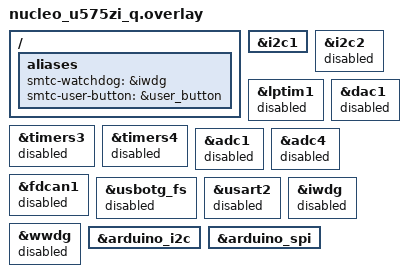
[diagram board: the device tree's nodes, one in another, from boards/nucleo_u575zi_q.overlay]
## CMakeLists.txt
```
# Copyright (c) 2024 Semtech Corporation
# SPDX-License-Identifier: Apache-2.0

cmake_minimum_required(VERSION 3.13.1)

find_package(Zephyr REQUIRED HINTS $ENV{ZEPHYR_BASE})
project(flrp_api_lorawan)

zephyr_include_directories(
  ${CMAKE_CURRENT_SOURCE_DIR}/src/
  ${CMAKE_CURRENT_SOURCE_DIR}/../../sdk/ranging_demo/src
)

target_sources(app PRIVATE
  ${CMAKE_CURRENT_SOURCE_DIR}/src/main.c
  ${CMAKE_CURRENT_SOURCE_DIR}/src/flrp_api.c
  ${CMAKE_CURRENT_SOURCE_DIR}/src/flrp_api_menu.c
  ${CMAKE_CURRENT_SOURCE_DIR}/src/flrp_remote.c
  ${CMAKE_CURRENT_SOURCE_DIR}/src/flrp_display.c
  ${CMAKE_CURRENT_SOURCE_DIR}/../../sdk/ranging_demo/src/oled_display.c
)
```

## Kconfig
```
# Copyright (c) 2026 Semtech Corporation
# SPDX-License-Identifier: Apache-2.0

menu "FLRP API lorawan sample defaults"

config FLRP_TEST_APPLY_DEFAULT_CONFIG
	bool "Apply FLRP testing defaults at boot (crypto off, fixed EUIs)"
	default n

config DISPLAY_THREAD_PRIORITY
	int "Display task priority"
	default 5
	help
	  Priority of the FLRP display task.

# Sample policy: enable sentinel only when MPU guard is off
config STACK_SENTINEL
	default y if !MPU_STACK_GUARD

config ICACHE
	default y if CPU_HAS_ICACHE

config DCACHE
	default y if CPU_HAS_DCACHE
	
config STM32_FLASH_PREFETCH
	depends on HAS_STM32_FLASH_PREFETCH
	default y

endmenu

source "Kconfig.zephyr"
```

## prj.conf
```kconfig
# Copyright (c) 2024 Semtech Corporation
# SPDX-License-Identifier: Apache-2.0

CONFIG_SPEED_OPTIMIZATIONS=y          # -O2 ou -O3
CONFIG_SIZE_OPTIMIZATIONS=n           # Vitesse > taille

# --------------------------- General configuration ---------------------------

CONFIG_USE_SEGGER_RTT=n

# heap size
CONFIG_HEAP_MEM_POOL_SIZE=4096

CONFIG_LOG=y

CONFIG_TEST_RANDOM_GENERATOR=y

CONFIG_PM_DEVICE=y

CONFIG_WATCHDOG=n

CONFIG_FLASH=y

CONFIG_I2C=y

CONFIG_EVENTS=y

# ------------------------------ Transceiver driver ----------------------------

CONFIG_LORA_BASICS_MODEM_DRIVERS=y
CONFIG_LORA_BASICS_MODEM_DRIVERS_EVENT_TRIGGER_GLOBAL_THREAD=n
CONFIG_LORA_BASICS_MODEM_DRIVERS_EVENT_TRIGGER_NO_THREAD=y

# ------------------------------ LoRa Basics Modem -----------------------------

CONFIG_USP_LORA_BASICS_MODEM=y

CONFIG_LORA_BASICS_MODEM_RELAY_TX=n

# ------------------------------ USP -----------------------------

CONFIG_USP=y
CONFIG_USP_FLRP=y
CONFIG_USP_MAIN_THREAD=y

#CONFIG_USP_LOG_LEVEL_DBG=y

CONFIG_MAIN_STACK_SIZE=4096

# Debug stack (à enlever en production)
CONFIG_THREAD_STACK_INFO=y
CONFIG_THREAD_MONITOR=y
CONFIG_THREAD_NAME=y

# Threads are cooperative (non-preemptive) to simplify critical section management and avoid complex synchronization.
# This approach may reduce reactivity when ISR (interrupt service routines) are triggered (low optimization)
# The USP RAC thread is assigned a higher priority: it will execute immediately once the Main thread yields or blocks, ensuring prompt handling of USP RAC-related tasks.
# The Main thread has a lower priority: it runs only when the USP RAC thread is idle or waiting
# CONFIG_DISPLAY_THREAD_PRIORITY=-1
# CONFIG_MAIN_THREAD_PRIORITY=-2
# CONFIG_USP_MAIN_THREAD_PRIORITY=-4


# Threads are preemptive: a thread with a higher priority can interrupt (preempt) a lower priority thread at any time.
# USP RAC thread has higher priority (1): it will preempt the main thread immediately whenever it is ready to run (ISR/Timer), ensuring low latency and fast response for USP RAC-related tasks.
# Main thread has lower priority (3): it runs only when the USP RAC thread is not active, yielding CPU time to the more urgent USP RAC operations automatically.
# This priority scheme allows responsive multitasking with guaranteed preemption based on thread priority.
CONFIG_DISPLAY_THREAD_PRIORITY=5
CONFIG_MAIN_THREAD_PRIORITY=3
CONFIG_USP_MAIN_THREAD_PRIORITY=1
# CONFIG_USP_THREADS_MUTEXES=y

#
# Priority Inversion : In case of multiple threads with different priorities, consider the modification of existing priorities and mutex use, or use Zephyr capabilities :
# CONFIG_KERNEL_MEM_POOL=y
# CONFIG_MUTEX_PRIORITY_INHERITANCE=y
# CONFIG_PRIORITY_CEILING=y



# Stack trace automatique
CONFIG_DEBUG_THREAD_INFO=y
CONFIG_THREAD_NAME=y
CONFIG_THREAD_STACK_INFO=y

# Meilleure trace des exceptions
CONFIG_EXTRA_EXCEPTION_INFO=y
CONFIG_FAULT_DUMP=2

# Symboles de debug
#CONFIG_DEBUG_INFO=y
CONFIG_DEBUG_OPTIMIZATIONS=y

# ------------------------------ Logging & Shell -----------------------------
CONFIG_LOG_TIMESTAMP_64BIT=y
CONFIG_LOG_OUTPUT_FORMAT_CUSTOM_TIMESTAMP=y
CONFIG_POSIX_API=y

# Shell Zephyr support
CONFIG_SHELL=y
CONFIG_SHELL_BACKENDS=y
CONFIG_SHELL_BACKEND_SERIAL=y

# Shell features
CONFIG_SHELL_HISTORY=y
CONFIG_SHELL_HISTORY_BUFFER=512
CONFIG_SHELL_TAB=y
CONFIG_SHELL_TAB_AUTOCOMPLETION=y

# Logs et Shell coexistence
CONFIG_SHELL_LOG_BACKEND=y
CONFIG_LOG_PROCESS_THREAD_STARTUP_DELAY_MS=1000
CONFIG_SHELL_PROMPT_UART="flrp_api:~$ "

# Shell stack size
CONFIG_SHELL_STACK_SIZE=4096

# Logging
CONFIG_LOG_MODE_DEFERRED=y
CONFIG_LOG_MODE_IMMEDIATE=n
#CONFIG_LOG_MODE_MINIMAL=y

# ------------------------------ Tests -----------------------------

# Skip the setup phase by applying the default configuration during initialization
CONFIG_FLRP_TEST_APPLY_DEFAULT_CONFIG=n
```

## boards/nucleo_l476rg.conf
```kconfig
# Uncomment those lines to activate DMA on STM32L476RG
CONFIG_DMA=y
CONFIG_DMA_STM32=y
CONFIG_SPI_STM32_DMA=y
CONFIG_SPI_STM32_INTERRUPT=n
CONFIG_SPI_ASYNC=n

#CONFIG_SPI_LOG_LEVEL_DBG=y
#CONFIG_NRFX_SPIM_LOG_LEVEL_DBG=y


## LPTIM
CONFIG_CORTEX_M_SYSTICK=n
CONFIG_STM32_LPTIM_TIMER=y
CONFIG_CLOCK_CONTROL=y
CONFIG_PM=y
CONFIG_RESET=y

# Custom PM policy
CONFIG_PM_DEVICE=n
CONFIG_PM_POLICY_CUSTOM=y
```

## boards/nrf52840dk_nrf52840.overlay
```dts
/*
 * Copyright (c) 2024 Semtech Corporation
 *
 * SPDX-License-Identifier: Apache-2.0
 */

#include "user_keys.overlay"

/ {
	aliases {
		smtc-watchdog = &wdt;
		smtc-user-button = &button0;
	};
};

&spi1 {
	status = "disabled";
};

&spi2 {
	status = "disabled";
};

&qspi {
	status = "disabled";
};

&wdt {
	status = "okay";
};

&arduino_i2c {
        /delete-property/ zephyr,concat-buf-size;
};
```

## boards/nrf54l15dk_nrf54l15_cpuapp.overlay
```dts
// /*
//  * Copyright (c) 2024 Semtech Corporation
//  *
//  * SPDX-License-Identifier: Apache-2.0
//  */

#include "user_keys.overlay"

/ {
	aliases {
		smtc-watchdog = &wdt31;
		smtc-user-button = &button0;
	};
};

// Set SPI freq @4MHz
&{/soc/peripheral@50000000/spi@4a000/lora@0} {
	spi-max-frequency = < 4000000 >;
};

// 	arduino_header: connector {
// 		compatible = "arduino-header-r3";
// 		#gpio-cells = <2>;
// 		gpio-map-mask = <0xffffffff 0xffffffc0>;
// 		gpio-map-pass-thru = <0 0x3f>;
// 		gpio-map = <0 0 &gpio1 4 0>,	/* A0 */
// 			   <1 0 &gpio0 4 0>,	/* A1 */ //NC 
// 			   <2 0 &gpio0 28 0>,	/* A2 */ //NC
// 			   <3 0 &gpio1 7 0>,	/* A3 */
// 			   <4 0 &gpio1 11 0>,	/* A4 */
// 			   <5 0 &gpio1 12 0>,	/* A5 */
// 			   <6 0 &gpio1 1 0>,	/* D0 */ //NC
// 			   <7 0 &gpio1 2 0>,	/* D1 */ //NC
// 			   <8 0 &gpio1 3 0>,	/* D2 */ //NC
// 			   <9 0 &gpio0 3 0>,	/* D3 */
// 			   <10 0 &gpio0 2 0>,	/* D4 */
// 			   <11 0 &gpio1 5 0>,	/* D5 */
// 			   <12 0 &gpio1 7 0>,	/* D6 */ //NC
// 			   <13 0 &gpio1 6 0>,	/* D7 */
// 			   <14 0 &gpio1 10 0>,	/* D8 */ //NC
// 			   <15 0 &gpio1 11 0>,	/* D9 */ //NC
// 			   <16 0 &gpio1 12 0>,	/* D10 */ //NC
// 			   <17 0 &gpio2 8 0>,	/* D11 */
// 			   <18 0 &gpio2 9 0>,	/* D12 */
// 			   <19 0 &gpio2 6 0>,	/* D13 */
// 			   <20 0 &gpio2 7 0>,	/* D14 */
// 			   <21 0 &gpio2 10 0>;	/* D15 */
// 	};
// };

// &spi1 {
// 	status = "disabled";
// };

// &spi2 {
// 	status = "disabled";
// };

// arduino_spi: &spi3 {
// 	status = "okay";
// 	cs-gpios = <&arduino_header 16 GPIO_ACTIVE_LOW>; /* D10 */
// 	pinctrl-0 = <&spi3_default>;
// 	pinctrl-1 = <&spi3_sleep>;
// 	pinctrl-names = "default", "sleep";
// };

// &qspi {
// 	status = "disabled";
// };

&uart20 {
	// status = "disabled";
	/delete-property/ hw-flow-control;
};

&pinctrl {
	uart20_default: uart20_default {
		group1 {
			psels = <NRF_PSEL(UART_TX, 1, 4)>,
				<NRF_PSEL(UART_RTS, 0, 2)>;
		};
		group2 {
			psels = <NRF_PSEL(UART_RX, 0, 1)>, //DIO9 is mapped on RX
				<NRF_PSEL(UART_CTS, 0, 3)>;
			bias-pull-up;
		};
	};

	uart20_sleep: uart20_sleep {
		group1 {
			psels = <NRF_PSEL(UART_TX, 1, 4)>,
				<NRF_PSEL(UART_RX, 0, 1)>,
				<NRF_PSEL(UART_RTS, 0, 2)>,
				<NRF_PSEL(UART_CTS, 0, 3)>;
			low-power-enable;
		};
	};
};

&wdt31 {
	status = "okay";
};
```

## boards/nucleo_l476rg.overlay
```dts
/*
 * Copyright (c) 2024 Semtech Corporation
 *
 * SPDX-License-Identifier: Apache-2.0
 */

#include "user_keys.overlay"

/ {
	aliases {
		smtc-watchdog = &iwdg;
		smtc-user-button = &user_button;
	};
};

&spi3 {
	status = "disabled";
};

&iwdg {
	status = "disabled";
};

&arduino_spi {
	/delete-property/ overrun-character;
};

&arduino_spi {
        /delete-property/ overrun-character;
        // Comment those 3 lines to deactivate DMA on STM32L4
        dmas = <&dma1 3 1 (STM32_DMA_PERIPH_TX | STM32_DMA_PRIORITY_HIGH)>,
               <&dma1 2 1 (STM32_DMA_PERIPH_RX | STM32_DMA_PRIORITY_HIGH)>;
        dma-names = "tx", "rx";
};

// Comment those 3 lines to deactivate DMA on STM32L4
&dma1 {
        status = "okay";
};



&arduino_i2c {
        /delete-property/ zephyr,concat-buf-size;
};

&lptim1 {
	clocks = <&rcc STM32_CLOCK_BUS_APB1 0x80000000>,
		 <&rcc STM32_SRC_LSE LPTIM1_SEL(3)>;
	status = "okay";
};

// Set SPI freq @10MHz for this sample
&{/soc/spi@40013000/lora@0} {
	spi-max-frequency = < 10000000 >; 
        pa-ramp-time = <17>; // 272us
};
```

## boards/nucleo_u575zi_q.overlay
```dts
/*
 * Copyright (c) 2024 Semtech Corporation
 *
 * SPDX-License-Identifier: Apache-2.0
 */

#include "user_keys.overlay"

/ {
	aliases {
		smtc-watchdog = &iwdg;
		smtc-user-button = &user_button;
	};
};

&i2c1 {
	status = "okay";
};

&i2c2 {
	status = "disabled";
};

&lptim1 {
	status = "disabled";
};

&timers3 {
	status = "disabled";
};

&timers4 {
	status = "disabled";
};

&dac1 {
	status = "disabled";
};

&adc1 {
	status = "disabled";
};

&adc4 {
	status = "disabled";
};

&fdcan1 {
	status = "disabled";
};

&usbotg_fs {
	status = "disabled";
};

&usart2 {
	status = "disabled";
};

&iwdg {
	status = "disabled";
};

&wwdg {
	status = "disabled";
};

&arduino_i2c {
        /delete-property/ zephyr,concat-buf-size;
};

&arduino_spi {
	/delete-property/ overrun-character;
};
```

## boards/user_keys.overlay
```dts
/*
 * Copyright (c) 2024 Semtech Corporation
 *
 * SPDX-License-Identifier: Apache-2.0
 */

/ {
	zephyr,user {
		user-lorawan-device-eui = <0x00 0x00 0x00 0x00 0x00 0x00 0x00 0x00>;
		user-lorawan-join-eui = <0x00 0x00 0x00 0x00 0x00 0x00 0x00 0x00>;
		user-lorawan-gen_app-key = <0x00 0x00 0x00 0x00 0x00 0x00 0x00 0x00
					    0x00 0x00 0x00 0x00 0x00 0x00 0x00 0x00>;
		user-lorawan-app-key = <0x00 0x00 0x00 0x00 0x00 0x00 0x00 0x00
						 0x00 0x00 0x00 0x00 0x00 0x00 0x00 0x00>;
		user-lorawan-region = "EU_868";
	};
};
```

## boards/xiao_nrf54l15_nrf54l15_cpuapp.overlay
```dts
// /*
//  * Copyright (c) 2024 Semtech Corporation
//  *
//  * SPDX-License-Identifier: Apache-2.0
//  */

#include "user_keys.overlay"

/ {
	aliases {
		smtc-watchdog = &wdt31;
		smtc-user-button = &usr_btn;
	};
};

&xiao_serial {
	status = "disabled";
};

&i2c22 {
	status = "okay";
};

&i2c30 {
	status = "disabled";
};

&adc {
	status = "disabled";
};

&wdt31 {
	status = "okay";
};

// Set pa ramp time to 272us for this sample
&{/soc/peripheral@50000000/spi@4a000/lora@0} {
        pa-ramp-time = <17>; // 272us
};
```

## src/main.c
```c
/*!
 * \file      main.c
 *
 * \brief     main program for FLRP API example
 *
 * The Clear BSD License
 * Copyright Semtech Corporation 2021. All rights reserved.
 *
 * Redistribution and use in source and binary forms, with or without
 * modification, are permitted (subject to the limitations in the disclaimer
 * below) provided that the following conditions are met:
 *     * Redistributions of source code must retain the above copyright
 *       notice, this list of conditions and the following disclaimer.
 *     * Redistributions in binary form must reproduce the above copyright
 *       notice, this list of conditions and the following disclaimer in the
 *       documentation and/or other materials provided with the distribution.
 *     * Neither the name of the Semtech corporation nor the
 *       names of its contributors may be used to endorse or promote products
 *       derived from this software without specific prior written permission.
 *
 * NO EXPRESS OR IMPLIED LICENSES TO ANY PARTY'S PATENT RIGHTS ARE GRANTED BY
 * THIS LICENSE. THIS SOFTWARE IS PROVIDED BY THE COPYRIGHT HOLDERS AND
 * CONTRIBUTORS "AS IS" AND ANY EXPRESS OR IMPLIED WARRANTIES, INCLUDING, BUT
 * NOT LIMITED TO, THE IMPLIED WARRANTIES OF MERCHANTABILITY AND FITNESS FOR A
 * PARTICULAR PURPOSE ARE DISCLAIMED. IN NO EVENT SHALL SEMTECH CORPORATION BE
 * LIABLE FOR ANY DIRECT, INDIRECT, INCIDENTAL, SPECIAL, EXEMPLARY, OR
 * CONSEQUENTIAL DAMAGES (INCLUDING, BUT NOT LIMITED TO, PROCUREMENT OF
 * SUBSTITUTE GOODS OR SERVICES; LOSS OF USE, DATA, OR PROFITS; OR BUSINESS
 * INTERRUPTION) HOWEVER CAUSED AND ON ANY THEORY OF LIABILITY, WHETHER IN
 * CONTRACT, STRICT LIABILITY, OR TORT (INCLUDING NEGLIGENCE OR OTHERWISE)
 * ARISING IN ANY WAY OUT OF THE USE OF THIS SOFTWARE, EVEN IF ADVISED OF THE
 * POSSIBILITY OF SUCH DAMAGE.
 */

/*
 * -----------------------------------------------------------------------------
 * --- DEPENDENCIES ------------------------------------------------------------
 */
#include <stdint.h>   // C99 types
#include <stdbool.h>  // bool type

#include <zephyr/kernel.h>
#include <zephyr/drivers/gpio.h>
#include <zephyr/devicetree.h>
#include <zephyr/device.h>
#include <zephyr/logging/log.h>

#define SMTC_HAL_DBG_TRACE_C
#include <smtc_hal_dbg_trace.h>
#include <smtc_sw_platform_helper.h>
#include <zephyr/lorawan_lbm/lorawan_hal_init.h>
#include <zephyr/usp/smtc_zephyr_log_custom.h>
#include <smtc_core_hal.h>
#include <smtc_modem_helper.h>

#include <smtc_rac_api.h>
#include <smtc_flrp_api.h>
#include "flrp_api.h"
#include "flrp_api_menu.h"
#include "main.h"
#include "flrp_remote.h"
#include "flrp_display.h"

/*
 * -----------------------------------------------------------------------------
 * --- PRIVATE MACROS-----------------------------------------------------------
 */

LOG_MODULE_REGISTER( flrp_api_lorawan, LOG_LEVEL_INF );

/*
 * -----------------------------------------------------------------------------
 * --- PRIVATE CONSTANTS -------------------------------------------------------
 */

/**
 * @brief Watchdog counter reload value during sleep (The period must be lower than MCU watchdog period (here 32s))
 */
#define WATCHDOG_RELOAD_PERIOD_MS 20000

/**
 * @brief Blue user button or BUTTON 1 on nrf52840-dk
 */

#define USER_BUTTON_NODE DT_ALIAS( smtc_user_button )
#if !DT_NODE_HAS_STATUS( USER_BUTTON_NODE, okay )
#error "Unsupported board: smtc-user-button devicetree alias is not defined"
#endif
static const struct gpio_dt_spec button = GPIO_DT_SPEC_GET_OR( USER_BUTTON_NODE, gpios, { 0 } );
static struct gpio_callback      button_cb_data;

/*
 * -----------------------------------------------------------------------------
 * --- PRIVATE TYPES -----------------------------------------------------------
 */

typedef struct user_button_s
{
    uint32_t last_press_timestamp;
} user_button_t;

/*
 * -----------------------------------------------------------------------------
 * --- PRIVATE VARIABLES -------------------------------------------------------
 */
static const uint32_t BUTTON_TRIGGER_DELAY = 500;  // ms

static user_button_t user_button = {
    .last_press_timestamp = 0,
};

/*
 * -----------------------------------------------------------------------------
 * --- PRIVATE FUNCTIONS DECLARATION -------------------------------------------
 */

static int  configure_user_button( void );
static void user_button_callback( const void* context );
void        button_pressed( const struct device* dev, struct gpio_callback* cb, uint32_t pins );

/*
 * -----------------------------------------------------------------------------
 * --- PUBLIC FUNCTIONS DEFINITION ---------------------------------------------
 */

/* An event to notify the main LBM loop */
K_EVENT_DEFINE( flrp_api_main_loop_event );

/**
 * @brief Example to send data using the Burst FLRP protocol
 *
 */
int main( void )
{
    flrp_api_event_t event = FLRP_API_EVENT_NONE;

    custom_log_init( 0 );
    flrp_display_init( );
    if( configure_user_button( ) != 0 )
    {
        SMTC_HAL_TRACE_ERROR( "Issue when configuring user button, aborting\n" );
        return 1;
    }

    SMTC_HAL_TRACE_INFO( "===== flrp api example  =====\r\n" );
    SMTC_SW_PLATFORM_INIT( );
    SMTC_SW_PLATFORM_VOID( smtc_rac_init( ) );
#if defined( CONFIG_FLRP_TEST_APPLY_DEFAULT_CONFIG )
    flrp_api_menu_apply_startup_test_defaults( );
#endif
#if defined( CONFIG_USP_LORA_BASICS_MODEM )
    SMTC_SW_PLATFORM_VOID( smtc_modem_init( &modem_event_callback ) );
    flrp_display_icon( 0, 2, ICON_RADIO_NOT_JOINED );
#endif

    // initialize LEDs
    init_leds( );
    set_led( SMTC_PF_LED_TX, false );
    set_led( SMTC_PF_LED_RX, false );

    while( true )
    {
#if !defined( CONFIG_USP_MAIN_THREAD )
        uint32_t sleep_time_ms = WATCHDOG_RELOAD_PERIOD_MS;
#if defined( CONFIG_USP_LORA_BASICS_MODEM )
        sleep_time_ms = smtc_modem_run_engine( );
#endif
        smtc_rac_run_engine( );
        smtc_flrp_run_engine( );
        if( smtc_rac_is_irq_flag_pending( ) )
        {
            continue;
        }
        // Allows waking up on radio event or push-button press
        if( smtc_flrp_call_run( ) == false )
        {
            struct k_sem* sems[] = { smtc_modem_hal_get_event_sem( ) };
            wait_on_sems_and_event( sems, 1, &flrp_api_main_loop_event, 0xFFFFFFFF,
                                    K_MSEC( MIN( sleep_time_ms, WATCHDOG_RELOAD_PERIOD_MS ) ) );
        }
        event = k_event_test( &flrp_api_main_loop_event, 0xFFFFFFFF );
#else
        event = k_event_wait( &flrp_api_main_loop_event, 0xFFFFFFFF, false, K_MSEC( WATCHDOG_RELOAD_PERIOD_MS ) );
#endif

        if( event & FLRP_API_EVENT_BUTTON_PRESS )
        {
            LOG_DBG( "Button pressed" );
            if( flrp_api_initiate_tx( flrp_api_menu_get_target_device_eui( ) ) != true )
            {
                LOG_ERR( "Failed to initiate transmission" );
            }
        }
        if( event & FLRP_API_EVENT_KEEPALIVE )
        {
            flrp_remote_send_keep_alive( );
        }
        k_event_clear( &flrp_api_main_loop_event, event );
        event = FLRP_API_EVENT_NONE;
    }
    return 0;
}

void main_loop_set_event( flrp_api_event_t event )
{
    k_event_set( &flrp_api_main_loop_event, event );
}

/*
 * -----------------------------------------------------------------------------
 * --- PRIVATE FUNCTIONS DEFINITION --------------------------------------------
 */

static void user_button_callback( const void* context )
{
    UNUSED( context );
    uint32_t timestamp = smtc_modem_hal_get_time_in_ms( );
    if( ( timestamp - user_button.last_press_timestamp ) > BUTTON_TRIGGER_DELAY )
    {
        user_button.last_press_timestamp = timestamp;
        /* Wake up the main thread */
        main_loop_set_event( FLRP_API_EVENT_BUTTON_PRESS );
    }
}

void button_pressed( const struct device* dev, struct gpio_callback* cb, uint32_t pins )
{
    printk( "%s", __func__ );
    user_button_callback( dev );
}

static int configure_user_button( void )
{
    int ret = 0;
    if( !gpio_is_ready_dt( &button ) )
    {
        printk( "Error: button device %s is not ready\n", button.port->name );
        return 1;
    }

    ret = gpio_pin_configure_dt( &button, GPIO_INPUT );
    if( ret != 0 )
    {
        printk( "Error %d: failed to configure %s pin %d\n", ret, button.port->name, button.pin );
        return 1;
    }

    ret = gpio_pin_interrupt_configure_dt( &button, GPIO_INT_EDGE_TO_ACTIVE );
    if( ret != 0 )
    {
        printk( "Error %d: failed to configure interrupt on %s pin %d\n", ret, button.port->name, button.pin );
        return 1;
    }

    gpio_init_callback( &button_cb_data, button_pressed, BIT( button.pin ) );
    gpio_add_callback( button.port, &button_cb_data );

    return 0;
}

/* --- EOF ------------------------------------------------------------------ */
```

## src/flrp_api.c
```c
/*!
 * \file      flrp_api.c
 *
 * \brief     Test functions for FLRP API example
 *
 * The Clear BSD License
 * Copyright Semtech Corporation 2021. All rights reserved.
 *
 * Redistribution and use in source and binary forms, with or without
 * modification, are permitted (subject to the limitations in the disclaimer
 * below) provided that the following conditions are met:
 *     * Redistributions of source code must retain the above copyright
 *       notice, this list of conditions and the following disclaimer.
 *     * Redistributions in binary form must reproduce the above copyright
 *       notice, this list of conditions and the following disclaimer in the
 *       documentation and/or other materials provided with the distribution.
 *     * Neither the name of the Semtech corporation nor the
 *       names of its contributors may be used to endorse or promote products
 *       derived from this software without specific prior written permission.
 *
 * NO EXPRESS OR IMPLIED LICENSES TO ANY PARTY'S PATENT RIGHTS ARE GRANTED BY
 * THIS LICENSE. THIS SOFTWARE IS PROVIDED BY THE COPYRIGHT HOLDERS AND
 * CONTRIBUTORS "AS IS" AND ANY EXPRESS OR IMPLIED WARRANTIES, INCLUDING, BUT
 * NOT LIMITED TO, THE IMPLIED WARRANTIES OF MERCHANTABILITY AND FITNESS FOR A
 * PARTICULAR PURPOSE ARE DISCLAIMED. IN NO EVENT SHALL SEMTECH CORPORATION BE
 * LIABLE FOR ANY DIRECT, INDIRECT, INCIDENTAL, SPECIAL, EXEMPLARY, OR
 * CONSEQUENTIAL DAMAGES (INCLUDING, BUT NOT LIMITED TO, PROCUREMENT OF
 * SUBSTITUTE GOODS OR SERVICES; LOSS OF USE, DATA, OR PROFITS; OR BUSINESS
 * INTERRUPTION) HOWEVER CAUSED AND ON ANY THEORY OF LIABILITY, WHETHER IN
 * CONTRACT, STRICT LIABILITY, OR TORT (INCLUDING NEGLIGENCE OR OTHERWISE)
 * ARISING IN ANY WAY OUT OF THE USE OF THIS SOFTWARE, EVEN IF ADVISED OF THE
 * POSSIBILITY OF SUCH DAMAGE.
 */

/*
 * -----------------------------------------------------------------------------
 * --- DEPENDENCIES ------------------------------------------------------------
 */
#include <stdio.h>
#include <stdint.h>   // C99 types
#include <stdbool.h>  // bool type
#include <stdarg.h>
#include <string.h>
#include <inttypes.h>

#include <zephyr/kernel.h>
#include <zephyr/logging/log.h>

#include <smtc_flrp_api.h>
#include <smtc_flrp_crypto.h>
#include <flrp_configuration.h>
#include "flrp_api.h"
#include "flrp_display.h"

/*
 * -----------------------------------------------------------------------------
 * --- PRIVATE MACROS-----------------------------------------------------------
 */

LOG_MODULE_REGISTER( flrp_api_tools, LOG_LEVEL_INF );

/*
 * -----------------------------------------------------------------------------
 * --- PRIVATE CONSTANTS -------------------------------------------------------
 */

#define DATA_SIZE ( 20 * 1024 )

/*
 * -----------------------------------------------------------------------------
 * --- PRIVATE TYPES -----------------------------------------------------------
 */
typedef struct flrp_api_message_s
{
    uint16_t counter;
    uint8_t  data[DATA_SIZE];
} flrp_api_message_t;

/*
 * -----------------------------------------------------------------------------
 * --- PRIVATE VARIABLES -------------------------------------------------------
 */
static uint16_t flrp_api_tx_counter = 0;

static flrp_api_message_t data_flrp = { 0 };

/* Cumulative reception stats */
static uint32_t total_nb_packets_received_ok  = 0;
static uint32_t total_nb_packets_check_error  = 0;
static uint32_t total_nb_packets_received_nok = 0;
static int32_t  last_rssi_mean                = 0;
static uint32_t total_payload_size            = 0;
static uint32_t total_payload_size_expected   = 0;

/*
 * -----------------------------------------------------------------------------
 * --- PRIVATE FUNCTIONS DECLARATION -------------------------------------------
 */

static void user_rx_callback( const void* context, smtc_flrp_return_code_t status, uint32_t payload_size,
                              uint8_t* src_addr, smtc_flrp_rx_stats_t payload_stats );
static void user_tx_callback( const void* context, smtc_flrp_return_code_t err_code, bool send_successful,
                              uint8_t* dest_addr, smtc_flrp_tx_stats_t flrp_stats );
static void flrp_api_setup_tx_buffer( void );

/*
 * -----------------------------------------------------------------------------
 * --- PUBLIC FUNCTIONS DEFINITION ---------------------------------------------
 */

bool flrp_api_init( uint8_t* device_eui, uint8_t* key, bool crypto_enabled, bool is_low_frequency, bool listening )
{
    smtc_flrp_api_config_t  flrp_config;
    smtc_flrp_return_code_t return_code;
    bool                    ret = true;

    flrp_config.crypto_enabled = crypto_enabled;
    flrp_config.freq_plan      = is_low_frequency ? SMTC_FLRP_FREQ_865MHz : SMTC_FLRP_FREQ_2GHz4;
    flrp_config.crystal_error  = 10;
    memcpy( ( void* ) flrp_config.dev_eui, ( void* ) device_eui, SMTC_FLRP_EUI_LENGTH );
    return_code = smtc_flrp_init( flrp_config, user_tx_callback, user_rx_callback, NULL );

    smtc_flrp_crypto_init( );
    ret = flrp_api_set_key( key );

    if( listening == true )
    {
        return_code |= smtc_flrp_start_periodic_listening( ( uint8_t* ) &data_flrp, sizeof( data_flrp ) );
        memset( ( void* ) &data_flrp, 0x00, sizeof( data_flrp ) );
        for( uint32_t i = 0; i < sizeof( data_flrp.data ); i++ )
        {
            data_flrp.data[i] = ( uint8_t ) i;
        }
        return_code |= smtc_flrp_slave_prepare_data_to_send( ( uint8_t* ) &data_flrp, sizeof( data_flrp ) );
    }

    if( ( return_code != SMTC_FLRP_RC_OK ) || ( ret != true ) )
    {
        ret = false;
        LOG_ERR( "Failed to start periodic RX (error %u)", return_code );
    }
    else
    {
        flrp_display_message( 0, 0, FLRP_DISPLAY_FONT_SIZE_SMALL, "FLRP %02X%02X%02X%02X%02X%02X%02X%02X->...",
                              device_eui[0], device_eui[1], device_eui[2], device_eui[3], device_eui[4], device_eui[5],
                              device_eui[6], device_eui[7] );
    }
    return ret;
}

bool flrp_api_initiate_tx( uint8_t* target_device_eui )
{
    bool ret = true;

    smtc_flrp_com_config_t com_config = {
        .com_mode             = SMTC_FLRP_BIDIRECTIONAL,
        .link_adaptation_mode = SMTC_FLRP_LINK_ADAPTATION_CHANNEL_SELECTION_ONLY,
    };
    memcpy( ( void* ) com_config.slave_dev_eui, ( void* ) target_device_eui, SMTC_FLRP_EUI_LENGTH );
    flrp_api_setup_tx_buffer( );

    smtc_flrp_return_code_t return_code =
        smtc_flrp_initiate_transmission( ( uint8_t* ) &data_flrp, sizeof( data_flrp ), com_config );
    if( return_code != SMTC_FLRP_RC_OK )
    {
        LOG_ERR( "Failed to initiate transmission (error %u)\n", return_code );
        ret = false;
    }

    return ret;
}

bool flrp_api_initiate_rx( uint8_t* target_device_eui )
{
    bool ret = true;

    smtc_flrp_com_config_t com_config = {
        .com_mode             = SMTC_FLRP_BIDIRECTIONAL,
        .link_adaptation_mode = SMTC_FLRP_LINK_ADAPTATION_CHANNEL_SELECTION_ONLY,
    };
    memcpy( ( void* ) com_config.slave_dev_eui, ( void* ) target_device_eui, SMTC_FLRP_EUI_LENGTH );
    memset( ( void* ) &data_flrp.data, 0x00, sizeof( data_flrp.data ) );

    smtc_flrp_return_code_t return_code =
        smtc_flrp_initiate_reception( ( uint8_t* ) &data_flrp, sizeof( data_flrp ), com_config );
    if( return_code != SMTC_FLRP_RC_OK )
    {
        LOG_ERR( "Failed to initiate reception (error %u)\n", return_code );
        ret = false;
    }

    return ret;
}

bool flrp_api_set_key( uint8_t* key )
{
    bool ret = true;

    smtc_flrp_crypto_return_code_t crypto_return_code = smtc_flrp_crypto_set_key( SMTC_SE_APP_KEY, key, 0 );
    if( crypto_return_code != SMTC_FLRP_CRYPTO_RC_SUCCESS )
    {
        LOG_ERR( "Failed to set key (error %u)\n", crypto_return_code );
        ret = false;
    }

    return ret;
}

void flrp_api_get_burst_target_per( uint8_t* burst_target_per )
{
    smtc_flrp_radio_config_t cfg = smtc_flrp_get_current_radio_config( );

    *burst_target_per = cfg.flrc.burst_target_per;
}

bool flrp_api_set_burst_target_per( uint8_t burst_target_per, bool restart_listening )
{
    smtc_flrp_return_code_t  return_code;
    smtc_flrp_radio_config_t cfg;

    smtc_flrp_stop_periodic_listening( );
    // No trigger to signal end of wor reception available yet
    k_sleep( K_MSEC( RESTART_WOR_RX_DELAY_MS *
                     2 ) );  // Ensure the previous listening has stopped before applying new config
    cfg                       = smtc_flrp_get_current_radio_config( );
    cfg.flrc.burst_target_per = burst_target_per;
    return_code               = smtc_flrp_set_new_radio_config( cfg );
    if( restart_listening == true )
    {
        return_code |= smtc_flrp_start_periodic_listening( ( uint8_t* ) &data_flrp, sizeof( data_flrp ) );
    }

    return ( bool ) ( return_code == SMTC_FLRP_RC_OK );
}

bool flrp_api_start_listening( void )
{
    bool ret = true;

    smtc_flrp_return_code_t return_code =
        smtc_flrp_start_periodic_listening( ( uint8_t* ) &data_flrp, sizeof( data_flrp ) );
    if( return_code != SMTC_FLRP_RC_OK )
    {
        LOG_ERR( "Failed to start periodic listening (error %u)\n", return_code );
        ret = false;
    }

    return ret;
}

bool flrp_api_stop_listening( void )
{
    bool ret = true;

    smtc_flrp_return_code_t return_code = smtc_flrp_stop_periodic_listening( );
    if( return_code != SMTC_FLRP_RC_OK )
    {
        LOG_ERR( "Failed to stop periodic listening (error %u)\n", return_code );
        ret = false;
    }

    return ret;
}

void flrp_api_display_rx_stats( void )
{
    LOG_INF( "Num packets OK         : %u", total_nb_packets_received_ok );
    LOG_INF( "Num packets check error: %u", total_nb_packets_check_error );
    LOG_INF( "Num packets NOK        : %u", total_nb_packets_received_nok );
    LOG_INF( "Total packets received : %u",
             total_nb_packets_received_ok + total_nb_packets_check_error + total_nb_packets_received_nok );
    LOG_INF( "Total received size    : %u", total_payload_size );
    LOG_INF( "Total expected size    : %u", total_payload_size_expected );
    LOG_INF( "Last burst mean RSSI   : %d dBm", last_rssi_mean );
}

/*
 * -----------------------------------------------------------------------------
 * --- PRIVATE FUNCTIONS DEFINITION --------------------------------------------
 */

static void user_rx_callback( const void* context, smtc_flrp_return_code_t status, uint32_t payload_size,
                              uint8_t* src_addr, smtc_flrp_rx_stats_t rx_stats )
{
    if( src_addr != NULL )
    {
        LOG_INF( "user_rx_callback %d %d 0x%02X%02X%02X%02X%02X%02X%02X%02X %d", status, payload_size, src_addr[0],
                 src_addr[1], src_addr[2], src_addr[3], src_addr[4], src_addr[5], src_addr[6], src_addr[7],
                 data_flrp.counter );
    }
    else
    {
        LOG_INF( "user_rx_callback %d %d (no src_addr) %d", status, payload_size, data_flrp.counter );
    }
    LOG_INF( "RX stats: nb pkt OK=%" PRIu32 ", nb pkt err=%" PRIu32 ", nb pkt Nok=%" PRIu32 ", "
             "rssi burst=%" PRId32 ", expected payload size=%" PRIu32 ", wor rssi=%" PRId16 ", wor snr=%" PRId8
             " -- Payload/burst effective bitrate: %" PRIu32 ".%06" PRIu32 " / %" PRIu32 ".%06" PRIu32 " Mbit/s",
             rx_stats.burst.nb_packets_received_ok, rx_stats.burst.nb_packets_check_error,
             rx_stats.burst.nb_packets_received_nok, rx_stats.burst.rssi_mean, rx_stats.burst.payload_size_expected,
             rx_stats.wor.rssi, rx_stats.wor.snr, rx_stats.burst.payload_bit_rate_bps / 1000000U,
             rx_stats.burst.payload_bit_rate_bps % 1000000U, rx_stats.burst.burst_bit_rate_bps / 1000000U,
             rx_stats.burst.burst_bit_rate_bps % 1000000U );

    total_nb_packets_received_ok += rx_stats.burst.nb_packets_received_ok;
    total_nb_packets_check_error += rx_stats.burst.nb_packets_check_error;
    total_nb_packets_received_nok += rx_stats.burst.nb_packets_received_nok;
    last_rssi_mean = rx_stats.burst.rssi_mean;
    total_payload_size_expected += rx_stats.burst.payload_size_expected;
    total_payload_size += payload_size;

    if( ( status == SMTC_FLRP_RC_OK ) && ( payload_size > sizeof( data_flrp.counter ) ) )
    {
        LOG_HEXDUMP_INF( data_flrp.data, MIN( 64, payload_size - sizeof( data_flrp.counter ) ),
                         "Received displayed data" );
        flrp_display_message( 0, 4, FLRP_DISPLAY_FONT_SIZE_BIG, " Rx   : %05d", data_flrp.counter );
    }
    flrp_api_setup_tx_buffer( );
}

static void user_tx_callback( const void* context, smtc_flrp_return_code_t err_code, bool send_successful,
                              uint8_t* dest_addr, smtc_flrp_tx_stats_t flrp_stats )
{
    if( dest_addr != NULL )
    {
        LOG_INF( "user_tx_callback %d %d 0x%02X%02X%02X%02X%02X%02X%02X%02X %d", err_code, send_successful,
                 dest_addr[0], dest_addr[1], dest_addr[2], dest_addr[3], dest_addr[4], dest_addr[5], dest_addr[6],
                 dest_addr[7], data_flrp.counter );
    }
    else
    {
        LOG_INF( "user_tx_callback %d %d (no dest_addr) %d", err_code, send_successful, data_flrp.counter );
    }

    if( ( err_code == SMTC_FLRP_RC_OK ) && ( send_successful == true ) )
    {
        LOG_HEXDUMP_INF( data_flrp.data, MIN( 64, sizeof( data_flrp.data ) ), "Transmitted displayed data" );
        flrp_display_message( 0, 6, FLRP_DISPLAY_FONT_SIZE_BIG, " Tx   : %05d", data_flrp.counter );
        flrp_api_tx_counter++;
    }
    flrp_api_setup_tx_buffer( );
}

static void flrp_api_setup_tx_buffer( void )
{
    memset( ( void* ) &data_flrp.data, 0x00, sizeof( data_flrp.data ) );
    data_flrp.counter = flrp_api_tx_counter;

    for( uint32_t i = 0; i < sizeof( data_flrp.data ); i++ )
    {
        data_flrp.data[i] = ( uint8_t ) i;
    }
}

/* --- EOF ------------------------------------------------------------------ */
```

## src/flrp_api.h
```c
/**
 * @file      flrp_api.h
 *
 * @brief     flrp api test function interface
 *
 * The Clear BSD License
 * Copyright Semtech Corporation 2025. All rights reserved.
 *
 * Redistribution and use in source and binary forms, with or without
 * modification, are permitted (subject to the limitations in the disclaimer
 * below) provided that the following conditions are met:
 *     * Redistributions of source code must retain the above copyright
 *       notice, this list of conditions and the following disclaimer.
 *     * Redistributions in binary form must reproduce the above copyright
 *       notice, this list of conditions and the following disclaimer in the
 *       documentation and/or other materials provided with the distribution.
 *     * Neither the name of the Semtech corporation nor the
 *       names of its contributors may be used to endorse or promote products
 *       derived from this software without specific prior written permission.
 *
 * NO EXPRESS OR IMPLIED LICENSES TO ANY PARTY'S PATENT RIGHTS ARE GRANTED BY
 * THIS LICENSE. THIS SOFTWARE IS PROVIDED BY THE COPYRIGHT HOLDERS AND
 * CONTRIBUTORS "AS IS" AND ANY EXPRESS OR IMPLIED WARRANTIES, INCLUDING, BUT
 * NOT LIMITED TO, THE IMPLIED WARRANTIES OF MERCHANTABILITY AND FITNESS FOR A
 * PARTICULAR PURPOSE ARE DISCLAIMED. IN NO EVENT SHALL SEMTECH CORPORATION BE
 * LIABLE FOR ANY DIRECT, INDIRECT, INCIDENTAL, SPECIAL, EXEMPLARY, OR
 * CONSEQUENTIAL DAMAGES (INCLUDING, BUT NOT LIMITED TO, PROCUREMENT OF
 * SUBSTITUTE GOODS OR SERVICES; LOSS OF USE, DATA, OR PROFITS; OR BUSINESS
 * INTERRUPTION) HOWEVER CAUSED AND ON ANY THEORY OF LIABILITY, WHETHER IN
 * CONTRACT, STRICT LIABILITY, OR TORT (INCLUDING NEGLIGENCE OR OTHERWISE)
 * ARISING IN ANY WAY OUT OF THE USE OF THIS SOFTWARE, EVEN IF ADVISED OF THE
 * POSSIBILITY OF SUCH DAMAGE.
 */

#ifndef FLRP_API_H
#define FLRP_API_H

#include <stdbool.h>
#include <stdint.h>

bool flrp_api_init( uint8_t* device_eui, uint8_t* key, bool crypto_enabled, bool is_low_frequency, bool listening );
bool flrp_api_initiate_tx( uint8_t* target_device_eui );
bool flrp_api_initiate_rx( uint8_t* target_device_eui );
bool flrp_api_set_key( uint8_t* key );
void flrp_api_get_burst_target_per( uint8_t* burst_target_per );
bool flrp_api_set_burst_target_per( uint8_t burst_target_per, bool restart_listening );
bool flrp_api_start_listening( void );
bool flrp_api_stop_listening( void );
void flrp_api_display_rx_stats( void );

#endif  // FLRP_API_H
```

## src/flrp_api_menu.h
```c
/**
 * @file      flrp_api_menu.h
 *
 * @brief     flrp api menu function interface
 *
 * The Clear BSD License
 * Copyright Semtech Corporation 2025. All rights reserved.
 *
 * Redistribution and use in source and binary forms, with or without
 * modification, are permitted (subject to the limitations in the disclaimer
 * below) provided that the following conditions are met:
 *     * Redistributions of source code must retain the above copyright
 *       notice, this list of conditions and the following disclaimer.
 *     * Redistributions in binary form must reproduce the above copyright
 *       notice, this list of conditions and the following disclaimer in the
 *       documentation and/or other materials provided with the distribution.
 *     * Neither the name of the Semtech corporation nor the
 *       names of its contributors may be used to endorse or promote products
 *       derived from this software without specific prior written permission.
 *
 * NO EXPRESS OR IMPLIED LICENSES TO ANY PARTY'S PATENT RIGHTS ARE GRANTED BY
 * THIS LICENSE. THIS SOFTWARE IS PROVIDED BY THE COPYRIGHT HOLDERS AND
 * CONTRIBUTORS "AS IS" AND ANY EXPRESS OR IMPLIED WARRANTIES, INCLUDING, BUT
 * NOT LIMITED TO, THE IMPLIED WARRANTIES OF MERCHANTABILITY AND FITNESS FOR A
 * PARTICULAR PURPOSE ARE DISCLAIMED. IN NO EVENT SHALL SEMTECH CORPORATION BE
 * LIABLE FOR ANY DIRECT, INDIRECT, INCIDENTAL, SPECIAL, EXEMPLARY, OR
 * CONSEQUENTIAL DAMAGES (INCLUDING, BUT NOT LIMITED TO, PROCUREMENT OF
 * SUBSTITUTE GOODS OR SERVICES; LOSS OF USE, DATA, OR PROFITS; OR BUSINESS
 * INTERRUPTION) HOWEVER CAUSED AND ON ANY THEORY OF LIABILITY, WHETHER IN
 * CONTRACT, STRICT LIABILITY, OR TORT (INCLUDING NEGLIGENCE OR OTHERWISE)
 * ARISING IN ANY WAY OUT OF THE USE OF THIS SOFTWARE, EVEN IF ADVISED OF THE
 * POSSIBILITY OF SUCH DAMAGE.
 */

#ifndef FLRP_API_MENU_H
#define FLRP_API_MENU_H

#include <stdbool.h>
#include <stdint.h>

bool     flrp_api_menu_is_set( void );
uint8_t* flrp_api_menu_get_device_eui( void );
uint8_t* flrp_api_menu_get_target_device_eui( void );
uint8_t* flrp_api_menu_get_key( void );
bool     flrp_api_menu_init( uint8_t* device_eui, uint8_t* key, bool crypto_enabled, bool is_low_frequency,
                             bool listening );
void     flrp_api_menu_apply_startup_test_defaults( void );
bool     flrp_api_menu_initiate_transfer( bool transmit, uint8_t* target_device_eui );
bool     flrp_api_menu_start_listening( void );
bool     flrp_api_menu_stop_listening( void );

#endif  // FLRP_API_MENU_H
```

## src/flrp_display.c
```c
/*!
 * \file      flrp_api.c
 *
 * \brief     Test functions for FLRP API example
 *
 * The Clear BSD License
 * Copyright Semtech Corporation 2021. All rights reserved.
 *
 * Redistribution and use in source and binary forms, with or without
 * modification, are permitted (subject to the limitations in the disclaimer
 * below) provided that the following conditions are met:
 *     * Redistributions of source code must retain the above copyright
 *       notice, this list of conditions and the following disclaimer.
 *     * Redistributions in binary form must reproduce the above copyright
 *       notice, this list of conditions and the following disclaimer in the
 *       documentation and/or other materials provided with the distribution.
 *     * Neither the name of the Semtech corporation nor the
 *       names of its contributors may be used to endorse or promote products
 *       derived from this software without specific prior written permission.
 *
 * NO EXPRESS OR IMPLIED LICENSES TO ANY PARTY'S PATENT RIGHTS ARE GRANTED BY
 * THIS LICENSE. THIS SOFTWARE IS PROVIDED BY THE COPYRIGHT HOLDERS AND
 * CONTRIBUTORS "AS IS" AND ANY EXPRESS OR IMPLIED WARRANTIES, INCLUDING, BUT
 * NOT LIMITED TO, THE IMPLIED WARRANTIES OF MERCHANTABILITY AND FITNESS FOR A
 * PARTICULAR PURPOSE ARE DISCLAIMED. IN NO EVENT SHALL SEMTECH CORPORATION BE
 * LIABLE FOR ANY DIRECT, INDIRECT, INCIDENTAL, SPECIAL, EXEMPLARY, OR
 * CONSEQUENTIAL DAMAGES (INCLUDING, BUT NOT LIMITED TO, PROCUREMENT OF
 * SUBSTITUTE GOODS OR SERVICES; LOSS OF USE, DATA, OR PROFITS; OR BUSINESS
 * INTERRUPTION) HOWEVER CAUSED AND ON ANY THEORY OF LIABILITY, WHETHER IN
 * CONTRACT, STRICT LIABILITY, OR TORT (INCLUDING NEGLIGENCE OR OTHERWISE)
 * ARISING IN ANY WAY OUT OF THE USE OF THIS SOFTWARE, EVEN IF ADVISED OF THE
 * POSSIBILITY OF SUCH DAMAGE.
 */

/*
 * -----------------------------------------------------------------------------
 * --- DEPENDENCIES ------------------------------------------------------------
 */
#include <stdio.h>
#include <stdint.h>   // C99 types
#include <stdbool.h>  // bool type
#include <stdarg.h>
#include <string.h>

#include <zephyr/kernel.h>
#include <zephyr/logging/log.h>

#include "flrp_display.h"
#if DT_HAS_CHOSEN( zephyr_display )
#include "oled_display.h"
#endif

/*
 * -----------------------------------------------------------------------------
 * --- PRIVATE MACROS-----------------------------------------------------------
 */

LOG_MODULE_REGISTER( flrp_display, LOG_LEVEL_INF );

/*
 * -----------------------------------------------------------------------------
 * --- PRIVATE TYPES -----------------------------------------------------------
 */

#define DISPLAY_MESSAGE_MAX_LEN 22

typedef struct flrp_display_str_s
{
    char                     text[DISPLAY_MESSAGE_MAX_LEN];
    flrp_display_font_size_t font_size;
} flrp_display_str_t;

typedef struct flrp_display_message_s
{
    uint8_t x;
    uint8_t y;
    bool    is_icon;
    union
    {
        flrp_display_str_t     str;
        flrp_display_icon_id_t icon_id;
    };
} flrp_display_message_t;

typedef struct flrp_display_icon_s
{
    uint8_t width;
    uint8_t height;
    const uint8_t ( *data )[];
} flrp_display_icon_t;

/*
 * -----------------------------------------------------------------------------
 * --- PRIVATE CONSTANTS -------------------------------------------------------
 */

#define DISPLAY_QUEUE_DEPTH 8
#define DISPLAY_THREAD_STACK 1024

#if DT_HAS_CHOSEN( zephyr_display )
static const flrp_display_icon_t icons[ICON_MAX] = {
    {
        // ICON_RADIO_NOT_JOINED,
        .width  = 16,
        .height = 1,
        .data   = ( const uint8_t ( * )[] ) &
                ( const uint8_t[1][16] ){
                    { 0x00, 0x00, 0x00, 0x00, 0x00, 0x00, 0x00, 0x18, 0x18, 0x00, 0x00, 0x00, 0x00, 0x00, 0x00, 0x00 },
                },
    },
    {
        // ICON_RADIO_JOINED,
        .width  = 16,
        .height = 1,
        .data   = ( const uint8_t ( * )[] ) &
                ( const uint8_t[1][16] ){
                    { 0x00, 0x00, 0x3C, 0x42, 0xBD, 0x42, 0x00, 0x18, 0x18, 0x00, 0x42, 0xBD, 0x42, 0x3C, 0x00, 0x00 },
                },
    },
};
#endif

/*
 * -----------------------------------------------------------------------------
 * --- PRIVATE VARIABLES -------------------------------------------------------
 */

K_MSGQ_DEFINE( flrp_api_display_msgq, sizeof( flrp_display_message_t ), DISPLAY_QUEUE_DEPTH, 4 );
K_THREAD_STACK_DEFINE( flrp_api_display_thread_stack, DISPLAY_THREAD_STACK );
static struct k_thread flrp_api_display_thread;
static bool            flrp_api_display_thread_started = false;

/*
 * -----------------------------------------------------------------------------
 * --- PRIVATE FUNCTIONS DECLARATION -------------------------------------------
 */

static void display_task( void* p1, void* p2, void* p3 );

/*
 * -----------------------------------------------------------------------------
 * --- PUBLIC FUNCTIONS DEFINITION ---------------------------------------------
 */

void flrp_display_init( void )
{
    if( flrp_api_display_thread_started == false )
    {
        k_thread_create( &flrp_api_display_thread, flrp_api_display_thread_stack,
                         K_THREAD_STACK_SIZEOF( flrp_api_display_thread_stack ), display_task, NULL, NULL, NULL,
                         CONFIG_DISPLAY_THREAD_PRIORITY, 0, K_NO_WAIT );
        flrp_api_display_thread_started = true;
    }

    flrp_display_message( 0, 0, FLRP_DISPLAY_FONT_SIZE_SMALL, "FLRP                 " );
    flrp_display_message( 0, 1, FLRP_DISPLAY_FONT_SIZE_SMALL, "  ->                 " );

    flrp_display_message( 0, 4, FLRP_DISPLAY_FONT_SIZE_BIG, " Rx   : ....." );
    flrp_display_message( 0, 6, FLRP_DISPLAY_FONT_SIZE_BIG, " Tx   : ....." );
}

void flrp_display_message( uint8_t x, uint8_t y, flrp_display_font_size_t font_size, const char* fmt, ... )
{
    flrp_display_message_t message = {
        .x             = x,
        .y             = y,
        .is_icon       = false,
        .str.font_size = font_size,
    };

    va_list args;
    va_start( args, fmt );
    vsnprintf( message.str.text, sizeof( message.str.text ), fmt, args );
    va_end( args );
    if( k_msgq_put( &flrp_api_display_msgq, &message, K_NO_WAIT ) != 0 )
    {
        LOG_WRN( "Display queue full, dropping message: %s", message.str.text );
    }
}

void flrp_display_icon( uint8_t x, uint8_t y, flrp_display_icon_id_t icon_id )
{
    flrp_display_message_t message = {
        .x       = x,
        .y       = y,
        .is_icon = true,
        .icon_id = icon_id,
    };

    if( k_msgq_put( &flrp_api_display_msgq, &message, K_NO_WAIT ) != 0 )
    {
        LOG_WRN( "Display queue full, dropping icon %d", icon_id );
    }
}

/*
 * -----------------------------------------------------------------------------
 * --- PRIVATE FUNCTIONS DEFINITION --------------------------------------------
 */

static void display_task( void* p1, void* p2, void* p3 )
{
    ARG_UNUSED( p1 );
    ARG_UNUSED( p2 );
    ARG_UNUSED( p3 );

    flrp_display_message_t message;

#if DT_HAS_CHOSEN( zephyr_display )
    oled_display_init( );
    oled_cls( );
#endif

    while( true )
    {
        k_msgq_get( &flrp_api_display_msgq, &message, K_FOREVER );
#if DT_HAS_CHOSEN( zephyr_display )
        if( message.is_icon == false )
        {
            oled_show_str( message.x, message.y, message.str.text, ( uint8_t ) message.str.font_size );
        }
        else
        {
            if( message.icon_id < ICON_MAX )
            {
                oled_write_bitmap( message.x, message.y, ( uint8_t* ) icons[message.icon_id].data,
                                   icons[message.icon_id].width, icons[message.icon_id].height );
            }
        }
#endif
        if( message.is_icon == false )
        {
            LOG_INF( "Display %s", message.str.text );
        }
        else
        {
            LOG_INF( "Display icon %d", message.icon_id );
        }
    }
}

/* --- EOF ------------------------------------------------------------------ */
```

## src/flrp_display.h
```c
/**
 * @file      flrp_display.h
 *
 * @brief     flrp display function interface
 *
 * The Clear BSD License
 * Copyright Semtech Corporation 2025. All rights reserved.
 *
 * Redistribution and use in source and binary forms, with or without
 * modification, are permitted (subject to the limitations in the disclaimer
 * below) provided that the following conditions are met:
 *     * Redistributions of source code must retain the above copyright
 *       notice, this list of conditions and the following disclaimer.
 *     * Redistributions in binary form must reproduce the above copyright
 *       notice, this list of conditions and the following disclaimer in the
 *       documentation and/or other materials provided with the distribution.
 *     * Neither the name of the Semtech corporation nor the
 *       names of its contributors may be used to endorse or promote products
 *       derived from this software without specific prior written permission.
 *
 * NO EXPRESS OR IMPLIED LICENSES TO ANY PARTY'S PATENT RIGHTS ARE GRANTED BY
 * THIS LICENSE. THIS SOFTWARE IS PROVIDED BY THE COPYRIGHT HOLDERS AND
 * CONTRIBUTORS "AS IS" AND ANY EXPRESS OR IMPLIED WARRANTIES, INCLUDING, BUT
 * NOT LIMITED TO, THE IMPLIED WARRANTIES OF MERCHANTABILITY AND FITNESS FOR A
 * PARTICULAR PURPOSE ARE DISCLAIMED. IN NO EVENT SHALL SEMTECH CORPORATION BE
 * LIABLE FOR ANY DIRECT, INDIRECT, INCIDENTAL, SPECIAL, EXEMPLARY, OR
 * CONSEQUENTIAL DAMAGES (INCLUDING, BUT NOT LIMITED TO, PROCUREMENT OF
 * SUBSTITUTE GOODS OR SERVICES; LOSS OF USE, DATA, OR PROFITS; OR BUSINESS
 * INTERRUPTION) HOWEVER CAUSED AND ON ANY THEORY OF LIABILITY, WHETHER IN
 * CONTRACT, STRICT LIABILITY, OR TORT (INCLUDING NEGLIGENCE OR OTHERWISE)
 * ARISING IN ANY WAY OUT OF THE USE OF THIS SOFTWARE, EVEN IF ADVISED OF THE
 * POSSIBILITY OF SUCH DAMAGE.
 */

#ifndef FLRP_DISPLAY_H
#define FLRP_DISPLAY_H

#include <stdint.h>

typedef enum
{
    FLRP_DISPLAY_FONT_SIZE_SMALL = 1,
    FLRP_DISPLAY_FONT_SIZE_BIG   = 2,
} flrp_display_font_size_t;

typedef enum
{
    ICON_RADIO_NOT_JOINED,
    ICON_RADIO_JOINED,
    ICON_MAX,
} flrp_display_icon_id_t;

void flrp_display_init( void );
void flrp_display_message( uint8_t x, uint8_t y, flrp_display_font_size_t font_size, const char* fmt, ... );
void flrp_display_icon( uint8_t x, uint8_t y, flrp_display_icon_id_t icon_id );

#endif  // FLRP_DISPLAY_H
```
